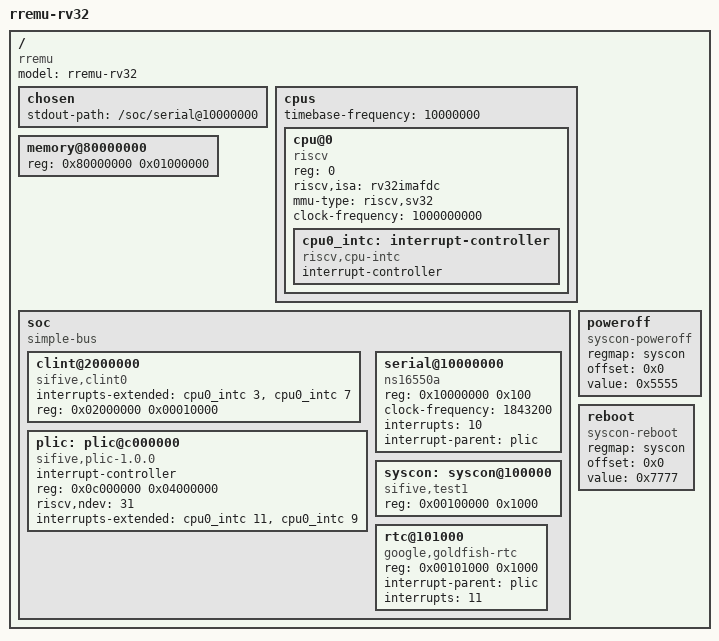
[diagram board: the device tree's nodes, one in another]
/dts-v1/;

/ {
    #address-cells = <1>;
    #size-cells = <1>;
    compatible = "rremu";
    model = "rremu-rv32";

    chosen {
        stdout-path = "/soc/serial@10000000";
    };

    cpus {
        #address-cells = <1>;
        #size-cells = <0>;
        timebase-frequency = <10000000>;

        cpu@0 {
            device_type = "cpu";
            compatible = "riscv";
            reg = <0>;
            status = "okay";
            riscv,isa = "rv32imafdc";
            mmu-type = "riscv,sv32";
            clock-frequency = <1000000000>;

            cpu0_intc: interrupt-controller {
                #interrupt-cells = <1>;
                interrupt-controller;
                compatible = "riscv,cpu-intc";
            };
        };
    };

    memory@80000000 {
        device_type = "memory";
        reg = <0x80000000 0x01000000>;
    };

    soc {
        #address-cells = <1>;
        #size-cells = <1>;
        compatible = "simple-bus";
        ranges;

        clint@2000000 {
            compatible = "sifive,clint0", "riscv,clint0";
            interrupts-extended = <&cpu0_intc 3 &cpu0_intc 7>;
            reg = <0x02000000 0x00010000>;
        };

        plic: plic@c000000 {
            compatible = "sifive,plic-1.0.0", "riscv,plic0";
            #address-cells = <0>;
            #interrupt-cells = <1>;
            interrupt-controller;
            reg = <0x0c000000 0x04000000>;
            riscv,ndev = <31>;
            interrupts-extended = <&cpu0_intc 11 &cpu0_intc 9>;
        };

        serial@10000000 {
            compatible = "ns16550a";
            reg = <0x10000000 0x100>;
            clock-frequency = <1843200>;
            interrupts = <10>;
            interrupt-parent = <&plic>;
        };

        syscon: syscon@100000 {
            compatible = "sifive,test1", "sifive,test0", "syscon";
            reg = <0x00100000 0x1000>;
        };

        rtc@101000 {
            compatible = "google,goldfish-rtc";
            reg = <0x00101000 0x1000>;
            interrupt-parent = <&plic>;
            interrupts = <11>;
        };
    };
    poweroff {
        compatible = "syscon-poweroff";
        regmap = <&syscon>;
        offset = <0x0>;
        value = <0x5555>;
    };

    reboot {
        compatible = "syscon-reboot";
        regmap = <&syscon>;
        offset = <0x0>;
        value = <0x7777>;
    };
};
